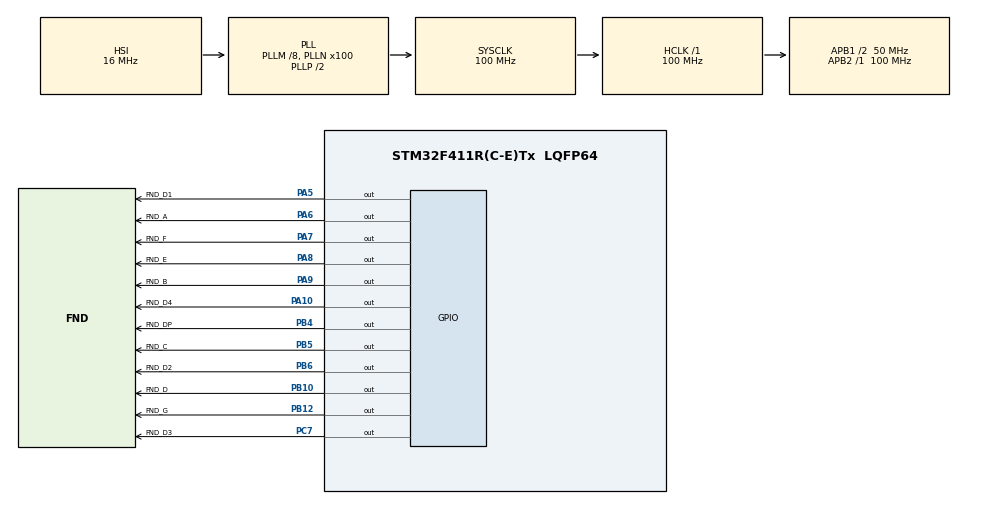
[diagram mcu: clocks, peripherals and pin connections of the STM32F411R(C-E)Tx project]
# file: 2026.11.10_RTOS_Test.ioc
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FREERTOS.Tasks01=defaultTask,0,128,StartDefaultTask,Default,NULL,Dynamic,NULL,NULL;myTask02,-3,128,StartTask02,Default,NULL,Dynamic,NULL,NULL
FREERTOS.configUSE_NEWLIB_REENTRANT=1
Mcu.Family=STM32F4
Mcu.Name=STM32F411R(C-E)Tx
Mcu.Package=LQFP64
NVIC.PriorityGroup=NVIC_PRIORITYGROUP_4
NVIC.TIM1_UP_TIM10_IRQn=true\:15\:0\:false\:false\:true\:false\:false\:true\:true
NVIC.TimeBase=TIM1_UP_TIM10_IRQn
NVIC.TimeBaseIP=TIM1
PA10.GPIO_Label=FND_D4
PA10.PinState=GPIO_PIN_SET
PA10.Signal=GPIO_Output
PA13.Mode=Trace_Asynchronous_SW
PA13.Signal=SYS_JTMS-SWDIO
PA14.Mode=Trace_Asynchronous_SW
PA14.Signal=SYS_JTCK-SWCLK
PA5.GPIO_Label=FND_D1
PA5.PinState=GPIO_PIN_SET
PA5.Signal=GPIO_Output
PA6.GPIO_Label=FND_A
PA6.Signal=GPIO_Output
PA7.GPIO_Label=FND_F
PA7.Signal=GPIO_Output
PA8.GPIO_Label=FND_E
PA8.Signal=GPIO_Output
PA9.GPIO_Label=FND_B
PA9.Signal=GPIO_Output
PB10.GPIO_Label=FND_D
PB10.Signal=GPIO_Output
PB12.GPIO_Label=FND_G
PB12.Signal=GPIO_Output
PB3.Mode=Trace_Asynchronous_SW
PB3.Signal=SYS_JTDO-SWO
PB4.GPIO_Label=FND_DP
PB4.Signal=GPIO_Output
PB5.GPIO_Label=FND_C
PB5.Signal=GPIO_Output
PB6.GPIO_Label=FND_D2
PB6.PinState=GPIO_PIN_SET
PB6.Signal=GPIO_Output
PC7.GPIO_Label=FND_D3
PC7.PinState=GPIO_PIN_SET
PC7.Signal=GPIO_Output
PH0\ -\ OSC_IN.Mode=HSE-External-Oscillator
PH0\ -\ OSC_IN.Signal=RCC_OSC_IN
PH1\ -\ OSC_OUT.Mode=HSE-External-Oscillator
PH1\ -\ OSC_OUT.Signal=RCC_OSC_OUT
ProjectManager.HeapSize=0x200
ProjectManager.StackSize=0x400
ProjectManager.TargetToolchain=STM32CubeIDE
RCC.48MHZClocksFreq_Value=50000000
RCC.AHBFreq_Value=100000000
RCC.APB1CLKDivider=RCC_HCLK_DIV2
RCC.APB1Freq_Value=50000000
RCC.APB1TimFreq_Value=100000000
RCC.APB2Freq_Value=100000000
RCC.APB2TimFreq_Value=100000000
RCC.CortexFreq_Value=100000000
RCC.HCLKFreq_Value=100000000
RCC.HSE_VALUE=8000000
RCC.HSI_VALUE=16000000
RCC.LSE_VALUE=32768
RCC.PLLM=8
RCC.PLLN=100
RCC.SYSCLKFreq_VALUE=100000000
RCC.SYSCLKSource=RCC_SYSCLKSOURCE_PLLCLK
RCC.VCOOutputFreq_Value=200000000
VP_FREERTOS_VS_CMSIS_V1.Mode=CMSIS_V1
VP_SYS_VS_tim1.Mode=TIM1
board=custom

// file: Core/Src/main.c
/* USER CODE BEGIN Header */
/**
 ******************************************************************************
 * @file           : main.c
 * @brief          : Main program body
 ******************************************************************************
 * @attention
 *
 * Copyright (c) 2026 STMicroelectronics.
 * All rights reserved.
 *
 * This software is licensed under terms that can be found in the LICENSE file
 * in the root directory of this software component.
 * If no LICENSE file comes with this software, it is provided AS-IS.
 *
 ******************************************************************************
 */
/* USER CODE END Header */
#include "main.h"
#include "cmsis_os.h"

/* USER CODE BEGIN Includes */
#include <stdio.h>

/* USER CODE END Includes */

osThreadId defaultTaskHandle;
osThreadId myTask02Handle;

void SystemClock_Config(void);
static void MX_GPIO_Init(void);
void StartDefaultTask(void const * argument);
void StartTask02(void const * argument);

/* USER CODE BEGIN 0 */
int __io_putchar(int ch)
{

	ITM_SendChar(ch);
	return ch;

}
/* USER CODE END 0 */

int main(void)
{

  /* MCU Configuration--------------------------------------------------------*/

  /* Reset of all peripherals, Initializes the Flash interface and the Systick. */
  HAL_Init();

  /* Configure the system clock */
  SystemClock_Config();

  /* Initialize all configured peripherals */
  MX_GPIO_Init();

  /* Create the thread(s) */
  /* definition and creation of defaultTask */
  osThreadDef(defaultTask, StartDefaultTask, osPriorityNormal, 0, 128);
  defaultTaskHandle = osThreadCreate(osThread(defaultTask), NULL);

  /* definition and creation of myTask02 */
  osThreadDef(myTask02, StartTask02, osPriorityIdle, 0, 128);
  myTask02Handle = osThreadCreate(osThread(myTask02), NULL);

  /* Start scheduler */
  osKernelStart();

  /* We should never get here as control is now taken by the scheduler */

  /* Infinite loop */
	while (1)
	{

	}
}

void SystemClock_Config(void)
{
  RCC_OscInitTypeDef RCC_OscInitStruct = {0};
  RCC_ClkInitTypeDef RCC_ClkInitStruct = {0};

  /** Configure the main internal regulator output voltage
  */
  __HAL_RCC_PWR_CLK_ENABLE();
  __HAL_PWR_VOLTAGESCALING_CONFIG(PWR_REGULATOR_VOLTAGE_SCALE1);

  /** Initializes the RCC Oscillators according to the specified parameters
  * in the RCC_OscInitTypeDef structure.
  */
  RCC_OscInitStruct.OscillatorType = RCC_OSCILLATORTYPE_HSI;
  RCC_OscInitStruct.HSIState = RCC_HSI_ON;
  RCC_OscInitStruct.HSICalibrationValue = RCC_HSICALIBRATION_DEFAULT;
  RCC_OscInitStruct.PLL.PLLState = RCC_PLL_ON;
  RCC_OscInitStruct.PLL.PLLSource = RCC_PLLSOURCE_HSI;
  RCC_OscInitStruct.PLL.PLLM = 8;
  RCC_OscInitStruct.PLL.PLLN = 100;
  RCC_OscInitStruct.PLL.PLLP = RCC_PLLP_DIV2;
  RCC_OscInitStruct.PLL.PLLQ = 4;
  if (HAL_RCC_OscConfig(&RCC_OscInitStruct) != HAL_OK)
  {
    Error_Handler();
  }

  /** Initializes the CPU, AHB and APB buses clocks
  */
  RCC_ClkInitStruct.ClockType = RCC_CLOCKTYPE_HCLK|RCC_CLOCKTYPE_SYSCLK
                              |RCC_CLOCKTYPE_PCLK1|RCC_CLOCKTYPE_PCLK2;
  RCC_ClkInitStruct.SYSCLKSource = RCC_SYSCLKSOURCE_PLLCLK;
  RCC_ClkInitStruct.AHBCLKDivider = RCC_SYSCLK_DIV1;
  RCC_ClkInitStruct.APB1CLKDivider = RCC_HCLK_DIV2;
  RCC_ClkInitStruct.APB2CLKDivider = RCC_HCLK_DIV1;

  if (HAL_RCC_ClockConfig(&RCC_ClkInitStruct, FLASH_LATENCY_3) != HAL_OK)
  {
    Error_Handler();
  }
}

static void MX_GPIO_Init(void)
{
  GPIO_InitTypeDef GPIO_InitStruct = {0};

  /* GPIO Ports Clock Enable */
  __HAL_RCC_GPIOH_CLK_ENABLE();
  __HAL_RCC_GPIOA_CLK_ENABLE();
  __HAL_RCC_GPIOB_CLK_ENABLE();
  __HAL_RCC_GPIOC_CLK_ENABLE();

  /*Configure GPIO pin Output Level */
  HAL_GPIO_WritePin(GPIOA, FND_D1_Pin|FND_D4_Pin, GPIO_PIN_SET);

  /*Configure GPIO pin Output Level */
  HAL_GPIO_WritePin(GPIOA, FND_A_Pin|FND_F_Pin|FND_E_Pin|FND_B_Pin, GPIO_PIN_RESET);

  /*Configure GPIO pin Output Level */
  HAL_GPIO_WritePin(GPIOB, FND_D_Pin|FND_G_Pin|FND_DP_Pin|FND_C_Pin, GPIO_PIN_RESET);

  /*Configure GPIO pin Output Level */
  HAL_GPIO_WritePin(FND_D3_GPIO_Port, FND_D3_Pin, GPIO_PIN_SET);

  /*Configure GPIO pin Output Level */
  HAL_GPIO_WritePin(FND_D2_GPIO_Port, FND_D2_Pin, GPIO_PIN_SET);

  /*Configure GPIO pins : FND_D1_Pin FND_A_Pin FND_F_Pin FND_E_Pin
                           FND_B_Pin FND_D4_Pin */
  GPIO_InitStruct.Pin = FND_D1_Pin|FND_A_Pin|FND_F_Pin|FND_E_Pin
                          |FND_B_Pin|FND_D4_Pin;
  GPIO_InitStruct.Mode = GPIO_MODE_OUTPUT_PP;
  GPIO_InitStruct.Pull = GPIO_NOPULL;
  GPIO_InitStruct.Speed = GPIO_SPEED_FREQ_LOW;
  HAL_GPIO_Init(GPIOA, &GPIO_InitStruct);

  /*Configure GPIO pins : FND_D_Pin FND_G_Pin FND_DP_Pin FND_C_Pin
                           FND_D2_Pin */
  GPIO_InitStruct.Pin = FND_D_Pin|FND_G_Pin|FND_DP_Pin|FND_C_Pin
                          |FND_D2_Pin;
  GPIO_InitStruct.Mode = GPIO_MODE_OUTPUT_PP;
  GPIO_InitStruct.Pull = GPIO_NOPULL;
  GPIO_InitStruct.Speed = GPIO_SPEED_FREQ_LOW;
  HAL_GPIO_Init(GPIOB, &GPIO_InitStruct);

  /*Configure GPIO pin : FND_D3_Pin */
  GPIO_InitStruct.Pin = FND_D3_Pin;
  GPIO_InitStruct.Mode = GPIO_MODE_OUTPUT_PP;
  GPIO_InitStruct.Pull = GPIO_NOPULL;
  GPIO_InitStruct.Speed = GPIO_SPEED_FREQ_LOW;
  HAL_GPIO_Init(FND_D3_GPIO_Port, &GPIO_InitStruct);

}

void StartDefaultTask(void const * argument)
{
  /* USER CODE BEGIN 5 */
	/* Infinite loop */
	for(;;)
	{
		HAL_GPIO_TogglePin(GPIOB, GPIO_PIN_14);
		printf("Task4: %lu\n", osKernelSysTick());
		osDelay(100);
	}
  /* USER CODE END 5 */
}

void StartTask02(void const * argument)
{
  /* USER CODE BEGIN StartTask02 */
	/* Infinite loop */
	for(;;)
	{
		HAL_GPIO_TogglePin(GPIOB, GPIO_PIN_14);
		printf("Task4: %lu\n", osKernelSysTick());
		osDelay(100);
		osDelay(1);
	}
  /* USER CODE END StartTask02 */
}

void HAL_TIM_PeriodElapsedCallback(TIM_HandleTypeDef *htim)
{
  if (htim->Instance == TIM1)
  {
    HAL_IncTick();
  }
}

void Error_Handler(void)
{
	__disable_irq();
	while (1)
	{
	}
}
